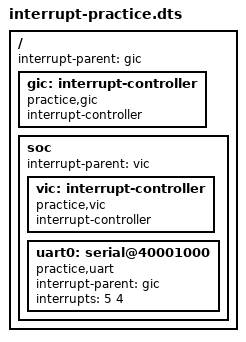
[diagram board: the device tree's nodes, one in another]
/dts-v1/;

/ {
    interrupt-parent = <&gic>;

    gic: interrupt-controller {
        compatible = "practice,gic";
        interrupt-controller;
        #interrupt-cells = <3>;
    };

    soc {
        interrupt-parent = <&vic>;

        vic: interrupt-controller {
            compatible = "practice,vic";
            interrupt-controller;
            #interrupt-cells = <2>;
        };

        uart0: serial@40001000 {
            interrupt-parent = <&gic>;
            compatible = "practice,uart";
            interrupts = <5 4>;
            status = "okay";
        };
    };
};
